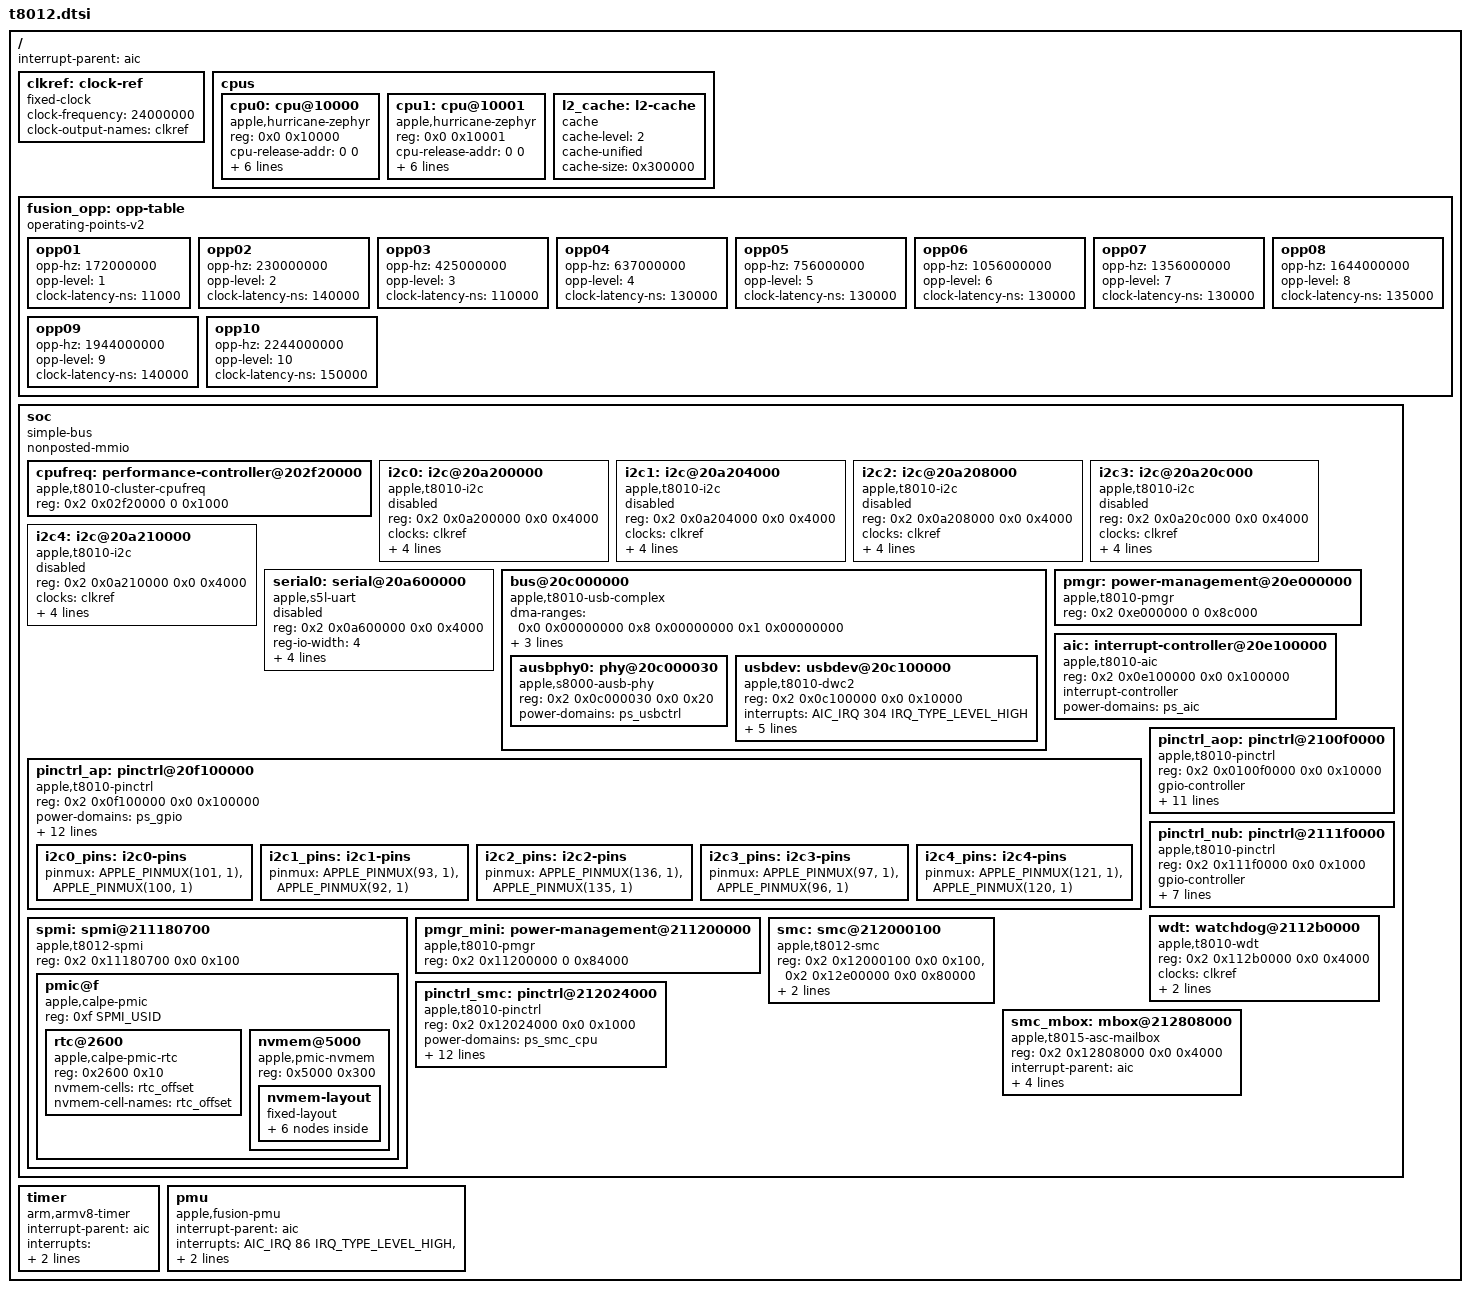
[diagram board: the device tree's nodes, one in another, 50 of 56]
// SPDX-License-Identifier: GPL-2.0+ OR MIT
/*
 * Apple T8012 "T2" SoC
 *
 * Other names: H9M, "Gibraltar"
 *
 * Copyright (c) 2024, Nick Chan <towinchenmi@gmail.com>
 */

#include <dt-bindings/gpio/gpio.h>
#include <dt-bindings/interrupt-controller/apple-aic.h>
#include <dt-bindings/interrupt-controller/irq.h>
#include <dt-bindings/phy/phy.h>
#include <dt-bindings/pinctrl/apple.h>
#include <dt-bindings/spmi/spmi.h>

/ {
	interrupt-parent = <&aic>;
	#address-cells = <2>;
	#size-cells = <2>;

	clkref: clock-ref {
		compatible = "fixed-clock";
		#clock-cells = <0>;
		clock-frequency = <24000000>;
		clock-output-names = "clkref";
	};

	cpus {
		#address-cells = <2>;
		#size-cells = <0>;

		cpu0: cpu@10000 {
			compatible = "apple,hurricane-zephyr";
			reg = <0x0 0x10000>;
			cpu-release-addr = <0 0>; /* To be filled by loader */
			operating-points-v2 = <&fusion_opp>;
			performance-domains = <&cpufreq>;
			enable-method = "spin-table";
			device_type = "cpu";
			next-level-cache = <&l2_cache>;
			i-cache-size = <0x10000>; /* P-core */
			d-cache-size = <0x10000>; /* P-core */
		};

		cpu1: cpu@10001 {
			compatible = "apple,hurricane-zephyr";
			reg = <0x0 0x10001>;
			cpu-release-addr = <0 0>; /* To be filled by loader */
			operating-points-v2 = <&fusion_opp>;
			performance-domains = <&cpufreq>;
			enable-method = "spin-table";
			device_type = "cpu";
			next-level-cache = <&l2_cache>;
			i-cache-size = <0x10000>; /* P-core */
			d-cache-size = <0x10000>; /* P-core */
		};

		l2_cache: l2-cache {
			compatible = "cache";
			cache-level = <2>;
			cache-unified;
			cache-size = <0x300000>; /* P-cluster */
		};
	};

	fusion_opp: opp-table {
		compatible = "operating-points-v2";

		/*
		 * Apple Fusion Architecture: Hardware big.LITTLE switcher
		 * that use p-state transitions to switch between cores.
		 * Only one type of core can be active at a given time.
		 *
		 * The E-core frequencies are adjusted so performance scales
		 * linearly with reported clock speed.
		 */

		opp01 {
			opp-hz = /bits/ 64 <172000000>; /* 300 MHz, E-core */
			opp-level = <1>;
			clock-latency-ns = <11000>;
		};
		opp02 {
			opp-hz = /bits/ 64 <230000000>; /* 396 MHz, E-core */
			opp-level = <2>;
			clock-latency-ns = <140000>;
		};
		opp03 {
			opp-hz = /bits/ 64 <425000000>; /* 732 MHz, E-core */
			opp-level = <3>;
			clock-latency-ns = <110000>;
		};
		opp04 {
			opp-hz = /bits/ 64 <637000000>; /* 1092 MHz, E-core */
			opp-level = <4>;
			clock-latency-ns = <130000>;
		};
		opp05 {
			opp-hz = /bits/ 64 <756000000>;
			opp-level = <5>;
			clock-latency-ns = <130000>;
		};
		opp06 {
			opp-hz = /bits/ 64 <1056000000>;
			opp-level = <6>;
			clock-latency-ns = <130000>;
		};
		opp07 {
			opp-hz = /bits/ 64 <1356000000>;
			opp-level = <7>;
			clock-latency-ns = <130000>;
		};
		opp08 {
			opp-hz = /bits/ 64 <1644000000>;
			opp-level = <8>;
			clock-latency-ns = <135000>;
		};
		opp09 {
			opp-hz = /bits/ 64 <1944000000>;
			opp-level = <9>;
			clock-latency-ns = <140000>;
		};
		opp10 {
			opp-hz = /bits/ 64 <2244000000>;
			opp-level = <10>;
			clock-latency-ns = <150000>;
		};
#if 0
		/* Not available until CPU deep sleep is implemented */
		opp11 {
			opp-hz = /bits/ 64 <2340000000>;
			opp-level = <11>;
			clock-latency-ns = <150000>;
			turbo-mode;
		};
#endif
	};

	soc {
		compatible = "simple-bus";
		#address-cells = <2>;
		#size-cells = <2>;
		nonposted-mmio;
		ranges;

		cpufreq: performance-controller@202f20000 {
			compatible = "apple,t8010-cluster-cpufreq", "apple,t8103-cluster-cpufreq", "apple,cluster-cpufreq";
			reg = <0x2 0x02f20000 0 0x1000>;
			#performance-domain-cells = <0>;
		};

		/* THESE I2C NODES DOES NOT WORK PROPERLY */
		i2c0: i2c@20a200000 {
			compatible = "apple,t8010-i2c", "apple,i2c";
			reg = <0x2 0x0a200000 0x0 0x4000>;
			clocks = <&clkref>;
			interrupt-parent = <&aic>;
			interrupts = <AIC_IRQ 294 IRQ_TYPE_LEVEL_HIGH>;
			pinctrl-0 = <&i2c0_pins>;
			pinctrl-names = "default";
			#address-cells = <0x1>;
			#size-cells = <0x0>;
			power-domains = <&ps_i2c0>;
			status = "disabled";
		};

		i2c1: i2c@20a204000 {
			compatible = "apple,t8010-i2c", "apple,i2c";
			reg = <0x2 0x0a204000 0x0 0x4000>;
			clocks = <&clkref>;
			interrupt-parent = <&aic>;
			interrupts = <AIC_IRQ 295 IRQ_TYPE_LEVEL_HIGH>;
			pinctrl-0 = <&i2c1_pins>;
			pinctrl-names = "default";
			#address-cells = <0x1>;
			#size-cells = <0x0>;
			power-domains = <&ps_i2c1>;
			status = "disabled";
		};

		i2c2: i2c@20a208000 {
			compatible = "apple,t8010-i2c", "apple,i2c";
			reg = <0x2 0x0a208000 0x0 0x4000>;
			clocks = <&clkref>;
			interrupt-parent = <&aic>;
			interrupts = <AIC_IRQ 296 IRQ_TYPE_LEVEL_HIGH>;
			pinctrl-0 = <&i2c2_pins>;
			pinctrl-names = "default";
			#address-cells = <0x1>;
			#size-cells = <0x0>;
			power-domains = <&ps_i2c2>;
			status = "disabled";
		};

		i2c3: i2c@20a20c000 {
			compatible = "apple,t8010-i2c", "apple,i2c";
			reg = <0x2 0x0a20c000 0x0 0x4000>;
			clocks = <&clkref>;
			interrupt-parent = <&aic>;
			interrupts = <AIC_IRQ 297 IRQ_TYPE_LEVEL_HIGH>;
			pinctrl-0 = <&i2c3_pins>;
			pinctrl-names = "default";
			#address-cells = <0x1>;
			#size-cells = <0x0>;
			power-domains = <&ps_i2c3>;
			status = "disabled";
		};

		i2c4: i2c@20a210000 {
			compatible = "apple,t8010-i2c", "apple,i2c";
			reg = <0x2 0x0a210000 0x0 0x4000>;
			clocks = <&clkref>;
			interrupt-parent = <&aic>;
			interrupts = <AIC_IRQ 298 IRQ_TYPE_LEVEL_HIGH>;
			pinctrl-0 = <&i2c4_pins>;
			pinctrl-names = "default";
			#address-cells = <0x1>;
			#size-cells = <0x0>;
			power-domains = <&ps_i2c4>;
			status = "disabled";
		};

		serial0: serial@20a600000 {
			compatible = "apple,s5l-uart";
			reg = <0x2 0x0a600000 0x0 0x4000>;
			reg-io-width = <4>;
			interrupt-parent = <&aic>;
			interrupts = <AIC_IRQ 271 IRQ_TYPE_LEVEL_HIGH>;
			/* Use the bootloader-enabled clocks for now. */
			clocks = <&clkref>, <&clkref>;
			clock-names = "uart", "clk_uart_baud0";
			power-domains = <&ps_uart0>;
			status = "disabled";
		};

		bus@20c000000 {
			compatible = "apple,t8010-usb-complex", "apple,s5l8960x-usb-complex", "simple-pm-bus";
			#address-cells = <2>;
			#size-cells = <2>;
			dma-ranges = <0x0 0x00000000 0x8 0x00000000 0x1 0x00000000>;
			nonposted-mmio;
			ranges;

			reg = <0x2 0x0c900000 0x0 0x100>;
			power-domains = <&ps_usb>;

			ausbphy0: phy@20c000030 {
				compatible = "apple,s8000-ausb-phy", "apple,ausb-phy";
				reg = <0x2 0x0c000030 0x0 0x20>;
				power-domains = <&ps_usbctrl>;
				#phy-cells = <1>;
				/* Tunables to be filled by loader */
			};

			usbdev: usbdev@20c100000 {
				compatible = "apple,t8010-dwc2", "apple,dwc2";
				reg = <0x2 0x0c100000 0x0 0x10000>;
				interrupts = <AIC_IRQ 304 IRQ_TYPE_LEVEL_HIGH>;
				clocks = <&clkref>;
				clock-names = "otg";
				phys = <&ausbphy0 PHY_TYPE_USB2>;
				phy-names = "usb2-phy";
				power-domains = <&ps_usbotg>;
				resets = <&ps_usbotg>;
				dr_mode = "peripheral";
			};
		};

		pmgr: power-management@20e000000 {
			compatible = "apple,t8010-pmgr", "apple,pmgr", "syscon", "simple-mfd";
			#address-cells = <1>;
			#size-cells = <1>;

			reg = <0x2 0xe000000 0 0x8c000>;
		};

		aic: interrupt-controller@20e100000 {
			compatible = "apple,t8010-aic", "apple,aic";
			reg = <0x2 0x0e100000 0x0 0x100000>;
			#interrupt-cells = <3>;
			interrupt-controller;
			power-domains = <&ps_aic>;
		};

		pinctrl_ap: pinctrl@20f100000 {
			compatible = "apple,t8010-pinctrl", "apple,pinctrl";
			reg = <0x2 0x0f100000 0x0 0x100000>;
			power-domains = <&ps_gpio>;

			gpio-controller;
			#gpio-cells = <2>;
			gpio-ranges = <&pinctrl_ap 0 0 221>;
			apple,npins = <221>;

			interrupt-controller;
			#interrupt-cells = <2>;
			interrupt-parent = <&aic>;
			interrupts = <AIC_IRQ 45 IRQ_TYPE_LEVEL_HIGH>,
				     <AIC_IRQ 46 IRQ_TYPE_LEVEL_HIGH>,
				     <AIC_IRQ 47 IRQ_TYPE_LEVEL_HIGH>,
				     <AIC_IRQ 48 IRQ_TYPE_LEVEL_HIGH>,
				     <AIC_IRQ 49 IRQ_TYPE_LEVEL_HIGH>,
				     <AIC_IRQ 50 IRQ_TYPE_LEVEL_HIGH>,
				     <AIC_IRQ 51 IRQ_TYPE_LEVEL_HIGH>;

			i2c0_pins: i2c0-pins {
				pinmux = <APPLE_PINMUX(101, 1)>,
					 <APPLE_PINMUX(100, 1)>;
			};

			i2c1_pins: i2c1-pins {
				pinmux = <APPLE_PINMUX(93, 1)>,
					 <APPLE_PINMUX(92, 1)>;
			};

			i2c2_pins: i2c2-pins {
				pinmux = <APPLE_PINMUX(136, 1)>,
					 <APPLE_PINMUX(135, 1)>;
			};

			i2c3_pins: i2c3-pins {
				pinmux = <APPLE_PINMUX(97, 1)>,
					 <APPLE_PINMUX(96, 1)>;
			};

			i2c4_pins: i2c4-pins {
				pinmux = <APPLE_PINMUX(121, 1)>,
					 <APPLE_PINMUX(120, 1)>;
			};
		};

		pinctrl_aop: pinctrl@2100f0000 {
			compatible = "apple,t8010-pinctrl", "apple,pinctrl";
			reg = <0x2 0x0100f0000 0x0 0x10000>;

			gpio-controller;
			#gpio-cells = <2>;
			gpio-ranges = <&pinctrl_aop 0 0 41>;
			apple,npins = <41>;

			interrupt-controller;
			#interrupt-cells = <2>;
			interrupt-parent = <&aic>;
			interrupts = <AIC_IRQ 131 IRQ_TYPE_LEVEL_HIGH>,
				     <AIC_IRQ 132 IRQ_TYPE_LEVEL_HIGH>,
				     <AIC_IRQ 133 IRQ_TYPE_LEVEL_HIGH>,
				     <AIC_IRQ 134 IRQ_TYPE_LEVEL_HIGH>,
				     <AIC_IRQ 135 IRQ_TYPE_LEVEL_HIGH>,
				     <AIC_IRQ 136 IRQ_TYPE_LEVEL_HIGH>,
				     <AIC_IRQ 137 IRQ_TYPE_LEVEL_HIGH>;
		};

		spmi: spmi@211180700 {
			compatible = "apple,t8012-spmi", "apple,t8103-spmi";
			reg = <0x2 0x11180700 0x0 0x100>;
			#address-cells = <2>;
			#size-cells = <0>;

			pmic@f {
				compatible = "apple,calpe-pmic", "apple,spmi-pmic";
				reg = <0xf SPMI_USID>;
				#address-cells = <1>;
				#size-cells = <1>;

				rtc@2600 {
					compatible = "apple,calpe-pmic-rtc";
					reg = <0x2600 0x10>;
					nvmem-cells = <&rtc_offset>;
					nvmem-cell-names = "rtc_offset";
				};

				nvmem@5000 {
					compatible = "apple,pmic-nvmem";
					reg = <0x5000 0x300>;

					nvmem-layout {
						compatible = "fixed-layout";
						#address-cells = <1>;
						#size-cells = <1>;

						boot_stage: boot-stage@1 {
							reg = <0x1 0x1>;
						};

						boot_error_count: boot-error-count@2,0 {
							reg = <0x2 0x1>;
							bits = <0 4>;
						};

						panic_count: panic-count@2,4 {
							reg = <0x2 0x1>;
							bits = <4 4>;
						};

						boot_error_stage: boot-error-stage@3 {
							reg = <0x3 0x1>;
						};

						rtc_offset: rtc-offset@4 {
							reg = <0x4 0x4>;
						};

						shutdown_flag: shutdown-flag@f {
							reg = <0xf 0x1>;
						};
					};
				};
			};
		};

		pinctrl_nub: pinctrl@2111f0000 {
			compatible = "apple,t8010-pinctrl", "apple,pinctrl";
			reg = <0x2 0x111f0000 0x0 0x1000>;

			gpio-controller;
			#gpio-cells = <2>;
			gpio-ranges = <&pinctrl_nub 0 0 19>;
			apple,npins = <19>;

			interrupt-controller;
			#interrupt-cells = <2>;
			interrupt-parent = <&aic>;
			interrupts = <AIC_IRQ 164 IRQ_TYPE_LEVEL_HIGH>,
				     <AIC_IRQ 165 IRQ_TYPE_LEVEL_HIGH>,
				     <AIC_IRQ 166 IRQ_TYPE_LEVEL_HIGH>;
		};

		pmgr_mini: power-management@211200000 {
			compatible = "apple,t8010-pmgr", "apple,pmgr", "syscon", "simple-mfd";
			#address-cells = <1>;
			#size-cells = <1>;

			reg = <0x2 0x11200000 0 0x84000>;
		};

		wdt: watchdog@2112b0000 {
			compatible = "apple,t8010-wdt", "apple,wdt";
			reg = <0x2 0x112b0000 0x0 0x4000>;
			clocks = <&clkref>;
			interrupt-parent = <&aic>;
			interrupts = <AIC_IRQ 168 IRQ_TYPE_LEVEL_HIGH>;
		};

		smc: smc@212000100 {
			compatible = "apple,t8012-smc", "apple,t8103-smc";
			reg = <0x2 0x12000100 0x0 0x100>,
				<0x2 0x12e00000 0x0 0x80000>;
			reg-names = "smc", "sram";
			mboxes = <&smc_mbox>;
			power-domains = <&ps_smc_cpu>;
		};

		pinctrl_smc: pinctrl@212024000 {
			compatible = "apple,t8010-pinctrl", "apple,pinctrl";
			reg = <0x2 0x12024000 0x0 0x1000>;
			power-domains = <&ps_smc_cpu>;

			gpio-controller;
			#gpio-cells = <2>;
			gpio-ranges = <&pinctrl_smc 0 0 81>;
			apple,npins = <81>;

			interrupt-controller;
			#interrupt-cells = <2>;
			interrupt-parent = <&aic>;
			interrupts = <AIC_IRQ 195 IRQ_TYPE_LEVEL_HIGH>,
				     <AIC_IRQ 196 IRQ_TYPE_LEVEL_HIGH>,
				     <AIC_IRQ 197 IRQ_TYPE_LEVEL_HIGH>,
				     <AIC_IRQ 198 IRQ_TYPE_LEVEL_HIGH>,
				     <AIC_IRQ 199 IRQ_TYPE_LEVEL_HIGH>,
				     <AIC_IRQ 200 IRQ_TYPE_LEVEL_HIGH>,
				     <AIC_IRQ 201 IRQ_TYPE_LEVEL_HIGH>;
		};

		smc_mbox: mbox@212808000 {
			compatible = "apple,t8015-asc-mailbox";
			reg = <0x2 0x12808000 0x0 0x4000>;
			interrupt-parent = <&aic>;
			interrupts = <AIC_IRQ 205 IRQ_TYPE_LEVEL_HIGH>,
				<AIC_IRQ 206 IRQ_TYPE_LEVEL_HIGH>,
				<AIC_IRQ 207 IRQ_TYPE_LEVEL_HIGH>,
				<AIC_IRQ 208 IRQ_TYPE_LEVEL_HIGH>;
			interrupt-names = "send-empty", "send-not-empty",
				"recv-empty", "recv-not-empty";
				#mbox-cells = <0>;
		};
	};

	timer {
		compatible = "arm,armv8-timer";
		interrupt-parent = <&aic>;
		interrupt-names = "phys", "virt";
		/* Note that T2 doesn't actually have a hypervisor (EL2 is not implemented). */
		interrupts = <AIC_FIQ AIC_TMR_GUEST_PHYS IRQ_TYPE_LEVEL_HIGH>,
			     <AIC_FIQ AIC_TMR_GUEST_VIRT IRQ_TYPE_LEVEL_HIGH>;
	};

	pmu {
		compatible = "apple,fusion-pmu";
		interrupt-parent = <&aic>;
		interrupts = <AIC_IRQ 86 IRQ_TYPE_LEVEL_HIGH>,
			     <AIC_IRQ 89 IRQ_TYPE_LEVEL_HIGH>;
		interrupt-affinity = <&cpu0 &cpu1>;
	};
};

#include "t8012-pmgr.dtsi"
